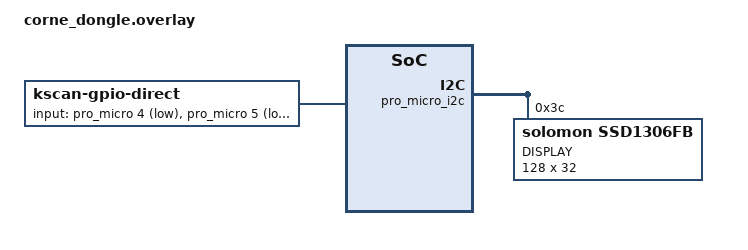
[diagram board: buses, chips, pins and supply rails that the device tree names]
#include <dt-bindings/zmk/matrix_transform.h>

/ {
    chosen {
        zmk,kscan = &kscan0;
        zmk,matrix_transform = &default_transform;
        zmk,display = &oled;
    };

    /* The 6-button direct GPIO setup (non-matrix) */
    kscan0: kscan {
        compatible = "zmk,kscan-gpio-direct";
        label = "KSCAN";
        input-gpios
            = <&pro_micro 4 (GPIO_ACTIVE_LOW | GPIO_PULL_UP)> // Button 1
            , <&pro_micro 5 (GPIO_ACTIVE_LOW | GPIO_PULL_UP)> // Button 2
            , <&pro_micro 6 (GPIO_ACTIVE_LOW | GPIO_PULL_UP)> // Button 3
            , <&pro_micro 7 (GPIO_ACTIVE_LOW | GPIO_PULL_UP)> // Button 4
            , <&pro_micro 8 (GPIO_ACTIVE_LOW | GPIO_PULL_UP)> // Button 5
            , <&pro_micro 9 (GPIO_ACTIVE_LOW | GPIO_PULL_UP)> // Button 6
            ;
    };

    /* Map the 6 physical buttons to the first 6 spots in the keymap */
    default_transform: matrix_transform {
        compatible = "zmk,matrix-transform";
        columns = <6>;
        rows = <1>;
        map = <RC(0,0) RC(0,1) RC(0,2) RC(0,3) RC(0,4) RC(0,5)>;
    };
};

/* OLED Configuration */
&pro_micro_i2c {
    status = "okay";
    oled: ssd1306@3c {
        compatible = "solomon,ssd1306fb";
        reg = <0x3c>;
        label = "DISPLAY";
        width = <128>;
        height = <32>;
        segment-offset = <0>;
        page-offset = <0>;
        display-offset = <0>;
        multiplex-ratio = <31>;
        com-invdir;
        segment-remap;
    };
};
